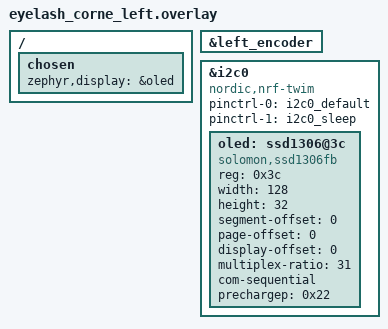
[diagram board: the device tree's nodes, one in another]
/*
*
* Copyright (c) 2024 The ZMK Contributors
* SPDX-License-Identifier: MIT
*
*/

#include "eyelash_corne.dtsi"
#include <behaviors/battery_history_request.dtsi>
#include <input/processors.dtsi>
#include <input/processors/runtime-input-processor.dtsi>

&left_encoder {
    status = "okay";
};

&i2c0 {
    status = "okay";
    compatible = "nordic,nrf-twim";
    pinctrl-0 = <&i2c0_default>;
    pinctrl-1 = <&i2c0_sleep>;
    pinctrl-names = "default", "sleep";
    oled: ssd1306@3c {
        compatible = "solomon,ssd1306fb";
        reg = <0x3c>;
        width = <128>;
        height = <32>;
        segment-offset = <0>;
        page-offset = <0>;
        display-offset = <0>;
        multiplex-ratio = <31>;
        com-sequential;
        prechargep = <0x22>;
    };
};

/ {
    chosen {
        zephyr,display = &oled;
    };
};
